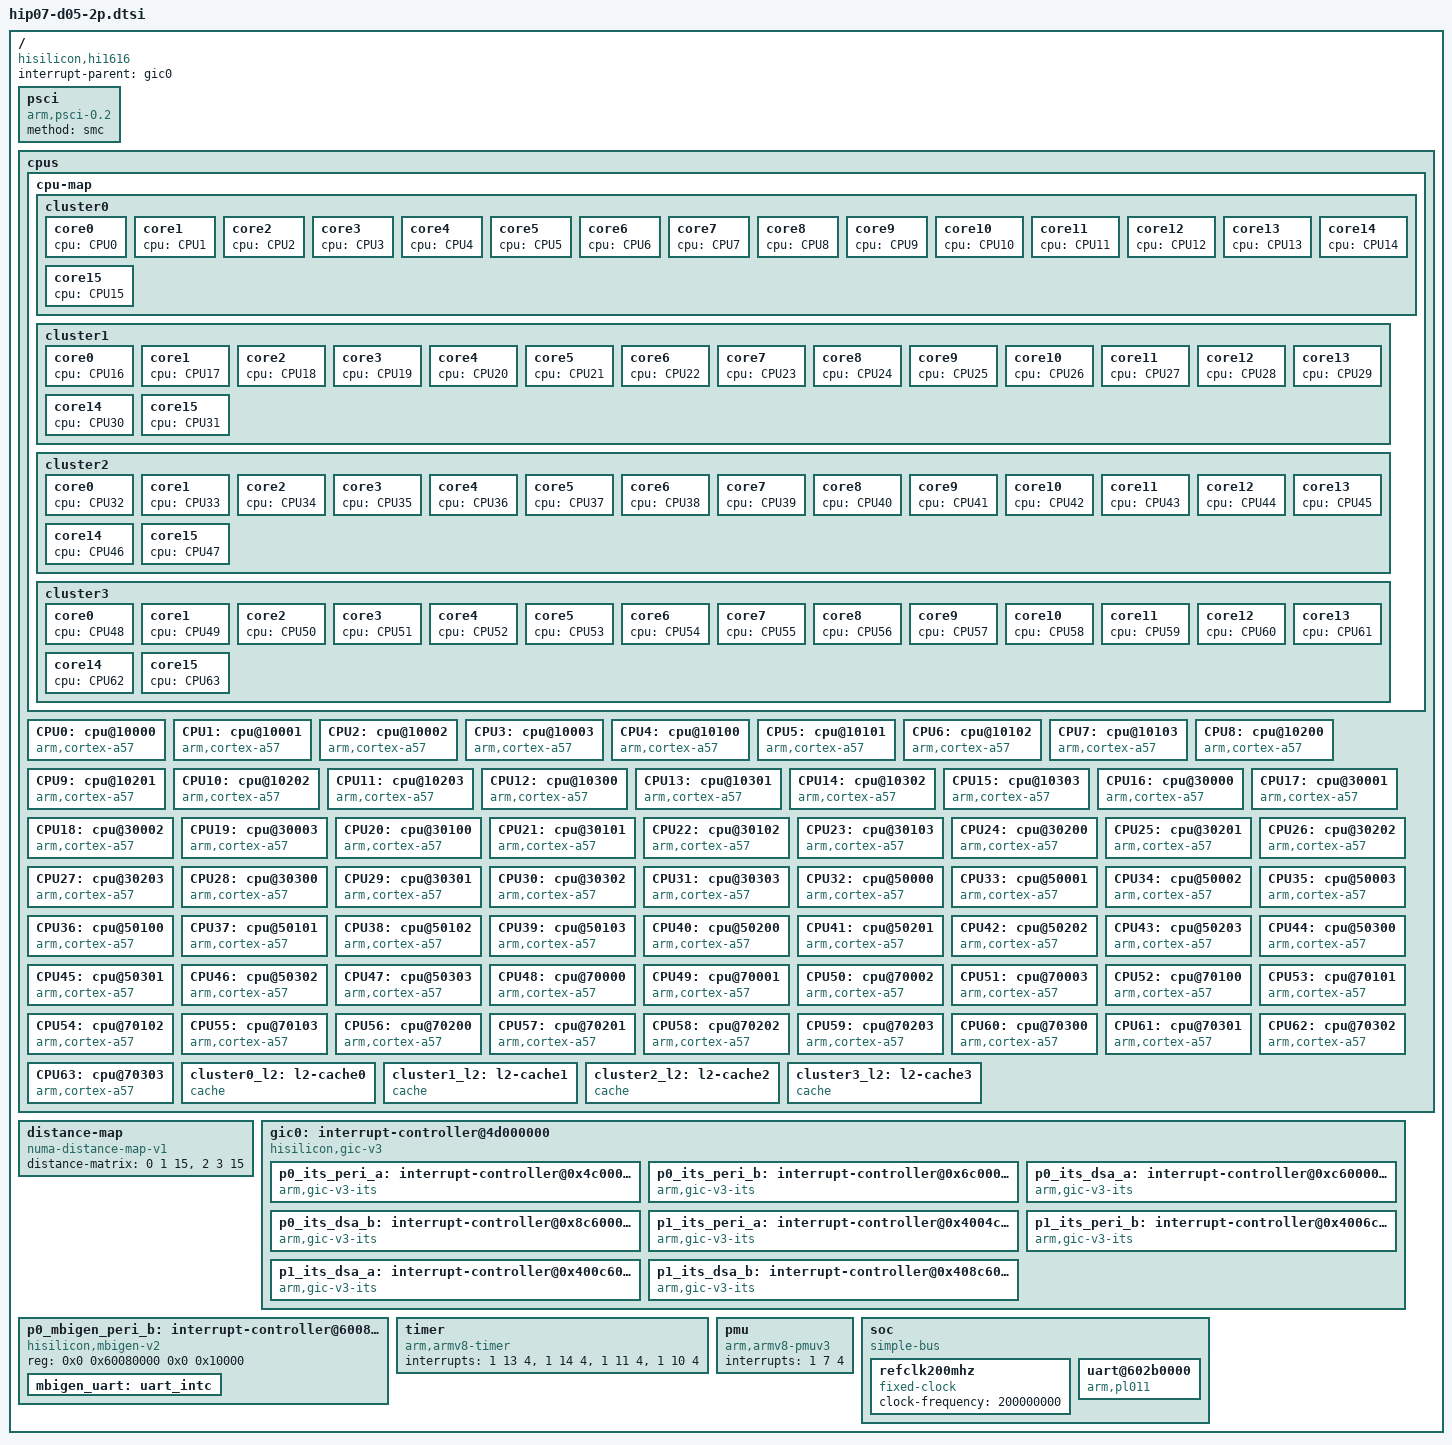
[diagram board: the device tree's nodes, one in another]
/**
 * dtsi file for Hisilicon Hi1616 Product Board
 *
 * Copyright (C) 2016 Hisilicon Ltd.
 *
 * This program is free software; you can redistribute it and/or modify
 * it under the terms of the GNU General Public License version 2 as
 * publishhed by the Free Software Foundation.
 *
 */

/ {
	#address-cells = <2>;
	#size-cells = <2>;
	compatible = "hisilicon,hi1616";
	interrupt-parent = <&gic0>;

	psci {
		compatible = "arm,psci-0.2";
		method = "smc";
	};

	cpus {
		#address-cells = <1>;
		#size-cells = <0>;

		cpu-map {
			cluster0 {
				core0 {
					cpu = <&CPU0>;
				};

				core1 {
					cpu = <&CPU1>;
				};

				core2 {
					cpu = <&CPU2>;
				};

				core3 {
					cpu = <&CPU3>;
				};

				core4 {
					cpu = <&CPU4>;
				};

				core5 {
					cpu = <&CPU5>;
				};

				core6 {
					cpu = <&CPU6>;
				};

				core7 {
					cpu = <&CPU7>;
				};

				core8 {
					cpu = <&CPU8>;
				};

				core9 {
					cpu = <&CPU9>;
				};

				core10 {
					cpu = <&CPU10>;
				};

				core11 {
					cpu = <&CPU11>;
				};

				core12 {
					cpu = <&CPU12>;
				};

				core13 {
					cpu = <&CPU13>;
				};

				core14 {
					cpu = <&CPU14>;
				};

				core15 {
					cpu = <&CPU15>;
				};
			};

			cluster1 {
				core0 {
					cpu = <&CPU16>;
				};

				core1 {
					cpu = <&CPU17>;
				};

				core2 {
					cpu = <&CPU18>;
				};

				core3 {
					cpu = <&CPU19>;
				};

				core4 {
					cpu = <&CPU20>;
				};

				core5 {
					cpu = <&CPU21>;
				};

				core6 {
					cpu = <&CPU22>;
				};

				core7 {
					cpu = <&CPU23>;
				};

				core8 {
					cpu = <&CPU24>;
				};

				core9 {
					cpu = <&CPU25>;
				};

				core10 {
					cpu = <&CPU26>;
				};

				core11 {
					cpu = <&CPU27>;
				};

				core12 {
					cpu = <&CPU28>;
				};

				core13 {
					cpu = <&CPU29>;
				};

				core14 {
					cpu = <&CPU30>;
				};

				core15 {
					cpu = <&CPU31>;
				};
			};

			cluster2 {
				core0 {
					cpu = <&CPU32>;
				};

				core1 {
					cpu = <&CPU33>;
				};

				core2 {
					cpu = <&CPU34>;
				};

				core3 {
					cpu = <&CPU35>;
				};

				core4 {
					cpu = <&CPU36>;
				};

				core5 {
					cpu = <&CPU37>;
				};

				core6 {
					cpu = <&CPU38>;
				};

				core7 {
					cpu = <&CPU39>;
				};

				core8 {
					cpu = <&CPU40>;
				};

				core9 {
					cpu = <&CPU41>;
				};

				core10 {
					cpu = <&CPU42>;
				};

				core11 {
					cpu = <&CPU43>;
				};

				core12 {
					cpu = <&CPU44>;
				};

				core13 {
					cpu = <&CPU45>;
				};

				core14 {
					cpu = <&CPU46>;
				};

				core15 {
					cpu = <&CPU47>;
				};
			};

			cluster3 {
				core0 {
					cpu = <&CPU48>;
				};

				core1 {
					cpu = <&CPU49>;
				};

				core2 {
					cpu = <&CPU50>;
				};

				core3 {
					cpu = <&CPU51>;
				};

				core4 {
					cpu = <&CPU52>;
				};

				core5 {
					cpu = <&CPU53>;
				};

				core6 {
					cpu = <&CPU54>;
				};

				core7 {
					cpu = <&CPU55>;
				};

				core8 {
					cpu = <&CPU56>;
				};

				core9 {
					cpu = <&CPU57>;
				};

				core10 {
					cpu = <&CPU58>;
				};

				core11 {
					cpu = <&CPU59>;
				};

				core12 {
					cpu = <&CPU60>;
				};

				core13 {
					cpu = <&CPU61>;
				};

				core14 {
					cpu = <&CPU62>;
				};

				core15 {
					cpu = <&CPU63>;
				};
			};
		};

		CPU0: cpu@10000 {
			device_type = "cpu";
			compatible = "arm,cortex-a57", "arm,armv8";
			reg = <0x10000>;
			enable-method = "psci";
			next-level-cache = <&cluster0_l2>;
			numa-node-id = <0>;
		};

		CPU1: cpu@10001 {
			device_type = "cpu";
			compatible = "arm,cortex-a57", "arm,armv8";
			reg = <0x10001>;
			enable-method = "psci";
			next-level-cache = <&cluster0_l2>;
			numa-node-id = <0>;
		};

		CPU2: cpu@10002 {
			device_type = "cpu";
			compatible = "arm,cortex-a57", "arm,armv8";
			reg = <0x10002>;
			enable-method = "psci";
			next-level-cache = <&cluster0_l2>;
			numa-node-id = <0>;
		};

		CPU3: cpu@10003 {
			device_type = "cpu";
			compatible = "arm,cortex-a57", "arm,armv8";
			reg = <0x10003>;
			enable-method = "psci";
			next-level-cache = <&cluster0_l2>;
			numa-node-id = <0>;
		};

		CPU4: cpu@10100 {
			device_type = "cpu";
			compatible = "arm,cortex-a57", "arm,armv8";
			reg = <0x10100>;
			enable-method = "psci";
			next-level-cache = <&cluster0_l2>;
			numa-node-id = <0>;
		};

		CPU5: cpu@10101 {
			device_type = "cpu";
			compatible = "arm,cortex-a57", "arm,armv8";
			reg = <0x10101>;
			enable-method = "psci";
			next-level-cache = <&cluster0_l2>;
			numa-node-id = <0>;
		};

		CPU6: cpu@10102 {
			device_type = "cpu";
			compatible = "arm,cortex-a57", "arm,armv8";
			reg = <0x10102>;
			enable-method = "psci";
			next-level-cache = <&cluster0_l2>;
			numa-node-id = <0>;
		};

		CPU7: cpu@10103 {
			device_type = "cpu";
			compatible = "arm,cortex-a57", "arm,armv8";
			reg = <0x10103>;
			enable-method = "psci";
			next-level-cache = <&cluster0_l2>;
			numa-node-id = <0>;
		};

		CPU8: cpu@10200 {
			device_type = "cpu";
			compatible = "arm,cortex-a57", "arm,armv8";
			reg = <0x10200>;
			enable-method = "psci";
			next-level-cache = <&cluster0_l2>;
			numa-node-id = <0>;
		};

		CPU9: cpu@10201 {
			device_type = "cpu";
			compatible = "arm,cortex-a57", "arm,armv8";
			reg = <0x10201>;
			enable-method = "psci";
			next-level-cache = <&cluster0_l2>;
			numa-node-id = <0>;
		};

		CPU10: cpu@10202 {
			device_type = "cpu";
			compatible = "arm,cortex-a57", "arm,armv8";
			reg = <0x10202>;
			enable-method = "psci";
			next-level-cache = <&cluster0_l2>;
			numa-node-id = <0>;
		};

		CPU11: cpu@10203 {
			device_type = "cpu";
			compatible = "arm,cortex-a57", "arm,armv8";
			reg = <0x10203>;
			enable-method = "psci";
			next-level-cache = <&cluster0_l2>;
			numa-node-id = <0>;
		};

		CPU12: cpu@10300 {
			device_type = "cpu";
			compatible = "arm,cortex-a57", "arm,armv8";
			reg = <0x10300>;
			enable-method = "psci";
			next-level-cache = <&cluster0_l2>;
			numa-node-id = <0>;
		};

		CPU13: cpu@10301 {
			device_type = "cpu";
			compatible = "arm,cortex-a57", "arm,armv8";
			reg = <0x10301>;
			enable-method = "psci";
			next-level-cache = <&cluster0_l2>;
			numa-node-id = <0>;
		};

		CPU14: cpu@10302 {
			device_type = "cpu";
			compatible = "arm,cortex-a57", "arm,armv8";
			reg = <0x10302>;
			enable-method = "psci";
			next-level-cache = <&cluster0_l2>;
			numa-node-id = <0>;
		};

		CPU15: cpu@10303 {
			device_type = "cpu";
			compatible = "arm,cortex-a57", "arm,armv8";
			reg = <0x10303>;
			enable-method = "psci";
			next-level-cache = <&cluster0_l2>;
			numa-node-id = <0>;
		};

		CPU16: cpu@30000 {
			device_type = "cpu";
			compatible = "arm,cortex-a57", "arm,armv8";
			reg = <0x30000>;
			enable-method = "psci";
			next-level-cache = <&cluster1_l2>;
			numa-node-id = <1>;
		};

		CPU17: cpu@30001 {
			device_type = "cpu";
			compatible = "arm,cortex-a57", "arm,armv8";
			reg = <0x30001>;
			enable-method = "psci";
			next-level-cache = <&cluster1_l2>;
			numa-node-id = <1>;
		};

		CPU18: cpu@30002 {
			device_type = "cpu";
			compatible = "arm,cortex-a57", "arm,armv8";
			reg = <0x30002>;
			enable-method = "psci";
			next-level-cache = <&cluster1_l2>;
			numa-node-id = <1>;
		};

		CPU19: cpu@30003 {
			device_type = "cpu";
			compatible = "arm,cortex-a57", "arm,armv8";
			reg = <0x30003>;
			enable-method = "psci";
			next-level-cache = <&cluster1_l2>;
			numa-node-id = <1>;
		};

		CPU20: cpu@30100 {
			device_type = "cpu";
			compatible = "arm,cortex-a57", "arm,armv8";
			reg = <0x30100>;
			enable-method = "psci";
			next-level-cache = <&cluster1_l2>;
			numa-node-id = <1>;
		};

		CPU21: cpu@30101 {
			device_type = "cpu";
			compatible = "arm,cortex-a57", "arm,armv8";
			reg = <0x30101>;
			enable-method = "psci";
			next-level-cache = <&cluster1_l2>;
			numa-node-id = <1>;
		};

		CPU22: cpu@30102 {
			device_type = "cpu";
			compatible = "arm,cortex-a57", "arm,armv8";
			reg = <0x30102>;
			enable-method = "psci";
			next-level-cache = <&cluster1_l2>;
			numa-node-id = <1>;
		};

		CPU23: cpu@30103 {
			device_type = "cpu";
			compatible = "arm,cortex-a57", "arm,armv8";
			reg = <0x30103>;
			enable-method = "psci";
			next-level-cache = <&cluster1_l2>;
			numa-node-id = <1>;
		};

		CPU24: cpu@30200 {
			device_type = "cpu";
			compatible = "arm,cortex-a57", "arm,armv8";
			reg = <0x30200>;
			enable-method = "psci";
			next-level-cache = <&cluster1_l2>;
			numa-node-id = <1>;
		};

		CPU25: cpu@30201 {
			device_type = "cpu";
			compatible = "arm,cortex-a57", "arm,armv8";
			reg = <0x30201>;
			enable-method = "psci";
			next-level-cache = <&cluster1_l2>;
			numa-node-id = <1>;
		};

		CPU26: cpu@30202 {
			device_type = "cpu";
			compatible = "arm,cortex-a57", "arm,armv8";
			reg = <0x30202>;
			enable-method = "psci";
			next-level-cache = <&cluster1_l2>;
			numa-node-id = <1>;
		};

		CPU27: cpu@30203 {
			device_type = "cpu";
			compatible = "arm,cortex-a57", "arm,armv8";
			reg = <0x30203>;
			enable-method = "psci";
			next-level-cache = <&cluster1_l2>;
			numa-node-id = <1>;
		};

		CPU28: cpu@30300 {
			device_type = "cpu";
			compatible = "arm,cortex-a57", "arm,armv8";
			reg = <0x30300>;
			enable-method = "psci";
			next-level-cache = <&cluster1_l2>;
			numa-node-id = <1>;
		};

		CPU29: cpu@30301 {
			device_type = "cpu";
			compatible = "arm,cortex-a57", "arm,armv8";
			reg = <0x30301>;
			enable-method = "psci";
			next-level-cache = <&cluster1_l2>;
			numa-node-id = <1>;
		};

		CPU30: cpu@30302 {
			device_type = "cpu";
			compatible = "arm,cortex-a57", "arm,armv8";
			reg = <0x30302>;
			enable-method = "psci";
			next-level-cache = <&cluster1_l2>;
			numa-node-id = <1>;
		};

		CPU31: cpu@30303 {
			device_type = "cpu";
			compatible = "arm,cortex-a57", "arm,armv8";
			reg = <0x30303>;
			enable-method = "psci";
			next-level-cache = <&cluster1_l2>;
			numa-node-id = <1>;
		};

		CPU32: cpu@50000 {
			device_type = "cpu";
			compatible = "arm,cortex-a57", "arm,armv8";
			reg = <0x50000>;
			enable-method = "psci";
			next-level-cache = <&cluster2_l2>;
			numa-node-id = <2>;
		};

		CPU33: cpu@50001 {
			device_type = "cpu";
			compatible = "arm,cortex-a57", "arm,armv8";
			reg = <0x50001>;
			enable-method = "psci";
			next-level-cache = <&cluster2_l2>;
			numa-node-id = <2>;
		};

		CPU34: cpu@50002 {
			device_type = "cpu";
			compatible = "arm,cortex-a57", "arm,armv8";
			reg = <0x50002>;
			enable-method = "psci";
			next-level-cache = <&cluster2_l2>;
			numa-node-id = <2>;
		};

		CPU35: cpu@50003 {
			device_type = "cpu";
			compatible = "arm,cortex-a57", "arm,armv8";
			reg = <0x50003>;
			enable-method = "psci";
			next-level-cache = <&cluster2_l2>;
			numa-node-id = <2>;
		};

		CPU36: cpu@50100 {
			device_type = "cpu";
			compatible = "arm,cortex-a57", "arm,armv8";
			reg = <0x50100>;
			enable-method = "psci";
			next-level-cache = <&cluster2_l2>;
			numa-node-id = <2>;
		};

		CPU37: cpu@50101 {
			device_type = "cpu";
			compatible = "arm,cortex-a57", "arm,armv8";
			reg = <0x50101>;
			enable-method = "psci";
			next-level-cache = <&cluster2_l2>;
			numa-node-id = <2>;
		};

		CPU38: cpu@50102 {
			device_type = "cpu";
			compatible = "arm,cortex-a57", "arm,armv8";
			reg = <0x50102>;
			enable-method = "psci";
			next-level-cache = <&cluster2_l2>;
			numa-node-id = <2>;
		};

		CPU39: cpu@50103 {
			device_type = "cpu";
			compatible = "arm,cortex-a57", "arm,armv8";
			reg = <0x50103>;
			enable-method = "psci";
			next-level-cache = <&cluster2_l2>;
			numa-node-id = <2>;
		};

		CPU40: cpu@50200 {
			device_type = "cpu";
			compatible = "arm,cortex-a57", "arm,armv8";
			reg = <0x50200>;
			enable-method = "psci";
			next-level-cache = <&cluster2_l2>;
			numa-node-id = <2>;
		};

		CPU41: cpu@50201 {
			device_type = "cpu";
			compatible = "arm,cortex-a57", "arm,armv8";
			reg = <0x50201>;
			enable-method = "psci";
			next-level-cache = <&cluster2_l2>;
			numa-node-id = <2>;
		};

		CPU42: cpu@50202 {
			device_type = "cpu";
			compatible = "arm,cortex-a57", "arm,armv8";
			reg = <0x50202>;
			enable-method = "psci";
			next-level-cache = <&cluster2_l2>;
			numa-node-id = <2>;
		};

		CPU43: cpu@50203 {
			device_type = "cpu";
			compatible = "arm,cortex-a57", "arm,armv8";
			reg = <0x50203>;
			enable-method = "psci";
			next-level-cache = <&cluster2_l2>;
			numa-node-id = <2>;
		};

		CPU44: cpu@50300 {
			device_type = "cpu";
			compatible = "arm,cortex-a57", "arm,armv8";
			reg = <0x50300>;
			enable-method = "psci";
			next-level-cache = <&cluster2_l2>;
			numa-node-id = <2>;
		};

		CPU45: cpu@50301 {
			device_type = "cpu";
			compatible = "arm,cortex-a57", "arm,armv8";
			reg = <0x50301>;
			enable-method = "psci";
			next-level-cache = <&cluster2_l2>;
			numa-node-id = <2>;
		};

		CPU46: cpu@50302 {
			device_type = "cpu";
			compatible = "arm,cortex-a57", "arm,armv8";
			reg = <0x50302>;
			enable-method = "psci";
			next-level-cache = <&cluster2_l2>;
			numa-node-id = <2>;
		};

		CPU47: cpu@50303 {
			device_type = "cpu";
			compatible = "arm,cortex-a57", "arm,armv8";
			reg = <0x50303>;
			enable-method = "psci";
			next-level-cache = <&cluster2_l2>;
			numa-node-id = <2>;
		};

		CPU48: cpu@70000 {
			device_type = "cpu";
			compatible = "arm,cortex-a57", "arm,armv8";
			reg = <0x70000>;
			enable-method = "psci";
			next-level-cache = <&cluster3_l2>;
			numa-node-id = <3>;
		};

		CPU49: cpu@70001 {
			device_type = "cpu";
			compatible = "arm,cortex-a57", "arm,armv8";
			reg = <0x70001>;
			enable-method = "psci";
			next-level-cache = <&cluster3_l2>;
			numa-node-id = <3>;
		};

		CPU50: cpu@70002 {
			device_type = "cpu";
			compatible = "arm,cortex-a57", "arm,armv8";
			reg = <0x70002>;
			enable-method = "psci";
			next-level-cache = <&cluster3_l2>;
			numa-node-id = <3>;
		};

		CPU51: cpu@70003 {
			device_type = "cpu";
			compatible = "arm,cortex-a57", "arm,armv8";
			reg = <0x70003>;
			enable-method = "psci";
			next-level-cache = <&cluster3_l2>;
			numa-node-id = <3>;
		};

		CPU52: cpu@70100 {
			device_type = "cpu";
			compatible = "arm,cortex-a57", "arm,armv8";
			reg = <0x70100>;
			enable-method = "psci";
			next-level-cache = <&cluster3_l2>;
			numa-node-id = <3>;
		};

		CPU53: cpu@70101 {
			device_type = "cpu";
			compatible = "arm,cortex-a57", "arm,armv8";
			reg = <0x70101>;
			enable-method = "psci";
			next-level-cache = <&cluster3_l2>;
			numa-node-id = <3>;
		};

		CPU54: cpu@70102 {
			device_type = "cpu";
			compatible = "arm,cortex-a57", "arm,armv8";
			reg = <0x70102>;
			enable-method = "psci";
			next-level-cache = <&cluster3_l2>;
			numa-node-id = <3>;
		};

		CPU55: cpu@70103 {
			device_type = "cpu";
			compatible = "arm,cortex-a57", "arm,armv8";
			reg = <0x70103>;
			enable-method = "psci";
			next-level-cache = <&cluster3_l2>;
			numa-node-id = <3>;
		};

		CPU56: cpu@70200 {
			device_type = "cpu";
			compatible = "arm,cortex-a57", "arm,armv8";
			reg = <0x70200>;
			enable-method = "psci";
			next-level-cache = <&cluster3_l2>;
			numa-node-id = <3>;
		};

		CPU57: cpu@70201 {
			device_type = "cpu";
			compatible = "arm,cortex-a57", "arm,armv8";
			reg = <0x70201>;
			enable-method = "psci";
			next-level-cache = <&cluster3_l2>;
			numa-node-id = <3>;
		};

		CPU58: cpu@70202 {
			device_type = "cpu";
			compatible = "arm,cortex-a57", "arm,armv8";
			reg = <0x70202>;
			enable-method = "psci";
			next-level-cache = <&cluster3_l2>;
			numa-node-id = <3>;
		};

		CPU59: cpu@70203 {
			device_type = "cpu";
			compatible = "arm,cortex-a57", "arm,armv8";
			reg = <0x70203>;
			enable-method = "psci";
			next-level-cache = <&cluster3_l2>;
			numa-node-id = <3>;
		};

		CPU60: cpu@70300 {
			device_type = "cpu";
			compatible = "arm,cortex-a57", "arm,armv8";
			reg = <0x70300>;
			enable-method = "psci";
			next-level-cache = <&cluster3_l2>;
			numa-node-id = <3>;
		};

		CPU61: cpu@70301 {
			device_type = "cpu";
			compatible = "arm,cortex-a57", "arm,armv8";
			reg = <0x70301>;
			enable-method = "psci";
			next-level-cache = <&cluster3_l2>;
			numa-node-id = <3>;
		};

		CPU62: cpu@70302 {
			device_type = "cpu";
			compatible = "arm,cortex-a57", "arm,armv8";
			reg = <0x70302>;
			enable-method = "psci";
			next-level-cache = <&cluster3_l2>;
			numa-node-id = <3>;
		};

		CPU63: cpu@70303 {
			device_type = "cpu";
			compatible = "arm,cortex-a57", "arm,armv8";
			reg = <0x70303>;
			enable-method = "psci";
			next-level-cache = <&cluster3_l2>;
			numa-node-id = <3>;
		};
		cluster0_l2: l2-cache0 {
			compatible = "cache";
		};

		cluster1_l2: l2-cache1 {
			compatible = "cache";
		};
		cluster2_l2: l2-cache2 {
			compatible = "cache";
		};
		cluster3_l2: l2-cache3 {
			compatible = "cache";
		};
	};

	distance-map {
		compatible = "numa-distance-map-v1";
		distance-matrix = <0 1 15>, <2 3 15>;
	};

	gic0: interrupt-controller@4d000000 {
		compatible = "hisilicon,gic-v3";
		#interrupt-cells = <3>;
		#address-cells = <2>;
		#size-cells = <2>;
		ranges;
		interrupt-controller;
		#redistributor-regions = <4>;
		redistributor-stride = <0x0 0x40000>;
		reg = <0x0 0x4d000000 0x0 0x10000>,	/* P0 GICD A*/
		      <0x0 0x4d100000 0x0 0x400000>,	/* P0 GICR A*/
		      <0x0 0x6d100000 0x0 0x400000>,	/* P0 GICR B*/
		      <0x400 0x4d100000 0x0 0x400000>,	/* P1 GICR A*/
		      <0x400 0x6d100000 0x0 0x400000>,	/* P1 GICR B*/
		      <0x0 0xfe000000 0x0 0x10000>,	/* GICC */
		      <0x0 0xfe010000 0x0 0x10000>,     /* GICH */
		      <0x0 0xfe020000 0x0 0x10000>;     /* GICV */
		interrupts = <1 9 0xff04>;

		p0_its_peri_a: interrupt-controller@0x4c000000 {
			compatible = "arm,gic-v3-its";
			msi-controller;
			reg = <0x0 0x4c000000 0x0 0x1000000>;
		};

		p0_its_peri_b: interrupt-controller@0x6c000000 {
			compatible = "arm,gic-v3-its";
			msi-controller;
			#msi-cells = <1>;
			reg = <0x0 0x6c000000 0x0 0x1000000>;
		};

		p0_its_dsa_a: interrupt-controller@0xc6000000 {
			compatible = "arm,gic-v3-its";
			msi-controller;
			#msi-cells = <1>;
			reg = <0x0 0xc6000000 0x0 0x1000000>;
		};

		p0_its_dsa_b: interrupt-controller@0x8c6000000 {
			compatible = "arm,gic-v3-its";
			msi-controller;
			#msi-cells = <1>;
			reg = <0x8 0xc6000000 0x0 0x1000000>;
		};

		p1_its_peri_a: interrupt-controller@0x4004c000000 {
			compatible = "arm,gic-v3-its";
			msi-controller;
			#msi-cells = <1>;
			reg = <0x400 0x4c000000 0x0 0x1000000>;
		};

		p1_its_peri_b: interrupt-controller@0x4006c000000 {
			compatible = "arm,gic-v3-its";
			msi-controller;
			#msi-cells = <1>;
			reg = <0x400 0x6c000000 0x0 0x1000000>;
		};

		p1_its_dsa_a: interrupt-controller@0x400c6000000 {
			compatible = "arm,gic-v3-its";
			msi-controller;
			#msi-cells = <1>;
			reg = <0x400 0xc6000000 0x0 0x1000000>;
		};

		p1_its_dsa_b: interrupt-controller@0x408c6000000 {
			compatible = "arm,gic-v3-its";
			msi-controller;
			#msi-cells = <1>;
			reg = <0x408 0xc6000000 0x0 0x1000000>;
		};
	};

	p0_mbigen_peri_b: interrupt-controller@60080000 {
		compatible = "hisilicon,mbigen-v2";
		reg = <0x0 0x60080000 0x0 0x10000>;
		
		mbigen_uart: uart_intc {
			msi-parent = <&p0_its_peri_b 0x120c7>;
			interrupt-controller;
			#interrupt-cells = <2>;
			num-pins=<1>;
		};
	};
/*		p0_mbigen_peri_a: interrupt-controller@40080000 {
			compatible = "hisilicon,mbigen-v2";
			reg = <0x0 0x40080000 0x0 0x10000>;
			msi-parent = <&p0_its_peri_a>;
			interrupt-controller;
			#interrupt-cells = <0x4>;
		};

		p0_mbigen_peri_b: interrupt-controller@60080000 {
			compatible = "hisilicon,mbigen-v2";
			msi-parent = <&p0_its_peri_b>;
			interrupt-controller;
			#interrupt-cells = <0x4>;
			reg = <0x0 0x60080000 0x0 0x10000>;
		};

		p0_mbigen_pcie_a: interrupt-controller@a0080000 {
			compatible = "hisilicon,mbigen-v2";
			msi-parent = <&p0_its_dsa_a>;
			interrupt-controller;
			#interrupt-cells = <4>;
			reg = <0x0 0xa0080000 0x0 0x10000>;
		};

		p0_mbigen_dsa_a: interrupt-controller@c0080000 {
			compatible = "hisilicon,mbigen-v2";
			msi-parent = <&p0_its_dsa_a>;
			interrupt-controller;
			#interrupt-cells = <4>;
			reg = <0x0 0xc0080000 0x0 0x10000>;
		};

		p0_mbigen_alg_a: interrupt-controller@d0080000 {
			compatible = "hisilicon,mbigen-v2";
			msi-parent = <&p0_its_dsa_a>;
			interrupt-controller;
			#interrupt-cells = <4>;
			reg = <0x0 0xd0080000 0x0 0x10000>;
		};

		p0_mbigen_pcie_b: interrupt-controller@8a0080000 {
			compatible = "hisilicon,mbigen-v2";
			msi-parent = <&p0_its_dsa_b>;
			interrupt-controller;
			#interrupt-cells = <4>;
			reg = <0x8 0xa0080000 0x0 0x10000>;
		};

		p0_mbigen_dsa_b: interrupt-controller@8c0080000 {
			compatible = "hisilicon,mbigen-v2";
			msi-parent = <&p0_its_dsa_b>;
			interrupt-controller;
			#interrupt-cells = <4>;
			reg = <0x8 0xc0080000 0x0 0x10000>;
		};

		p0_mbigen_alg_b: interrupt-controller@8d0080000 {
			compatible = "hisilicon,mbigen-v2";
			msi-parent = <&p0_its_dsa_b>;
			interrupt-controller;
			#interrupt-cells = <4>;
			reg = <0x8 0xd0080000 0x0 0x10000>;
		};
*/
	timer {
		compatible = "arm,armv8-timer";
		interrupts = <1 13 4>,
			     <1 14 4>,
			     <1 11 4>,
			     <1 10 4>;
	};

	pmu {
		compatible = "arm,armv8-pmuv3";
		interrupts = <1 7 4>;
	};

	soc {
		compatible = "simple-bus";
		#address-cells = <2>;
		#size-cells = <2>;
		ranges;

		refclk200mhz: refclk200mhz {
			compatible = "fixed-clock";
			#clock-cells = <0>;
			clock-frequency = <200000000>;
		};



		uart@602b0000 {
			compatible = "arm,pl011", "arm,primecell";
			reg = <0x0 0x602b0000 0x0 0x1000>;
			interrupt-parent = <&mbigen_uart>;
			interrupts = <807 4>;
			clocks = <&refclk200mhz>, <&refclk200mhz>;
			clock-names = "uartclk", "apb_pclk";
		};

	};
};
